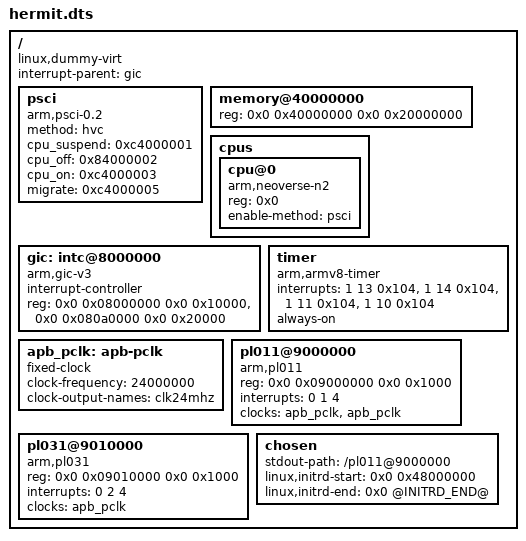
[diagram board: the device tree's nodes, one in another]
/*
 * N1.3: the board the Chitala image (Hermit) sees inside its VM: QEMU virt's
 * devices, as many as the VMM gives it and no more. RAM, one CPU, the GICv3
 * libvmm emulates, the architected timer (the guest uses the non-secure
 * physical one, passed through), the PL011 UART and the PL031 RTC (both
 * passed through), and PSCI. No PCI and no virtio: the guest finds none.
 * The image comes as the initrd; @INITRD_END@ is set when the image is built in.
 *
 * SPDX-License-Identifier: Apache-2.0
 */
/dts-v1/;

/ {
	interrupt-parent = <&gic>;
	#address-cells = <2>;
	#size-cells = <2>;
	compatible = "linux,dummy-virt";

	psci {
		compatible = "arm,psci-0.2", "arm,psci";
		method = "hvc";
		cpu_suspend = <0xc4000001>;
		cpu_off = <0x84000002>;
		cpu_on = <0xc4000003>;
		migrate = <0xc4000005>;
	};

	memory@40000000 {
		device_type = "memory";
		reg = <0x0 0x40000000 0x0 0x20000000>;
	};

	cpus {
		#address-cells = <1>;
		#size-cells = <0>;

		cpu@0 {
			device_type = "cpu";
			compatible = "arm,neoverse-n2";
			reg = <0x0>;
			enable-method = "psci";
		};
	};

	gic: intc@8000000 {
		compatible = "arm,gic-v3";
		#interrupt-cells = <3>;
		interrupt-controller;
		#address-cells = <2>;
		#size-cells = <2>;
		ranges;
		reg = <0x0 0x08000000 0x0 0x10000>,	/* distributor */
		      <0x0 0x080a0000 0x0 0x20000>;	/* redistributor: one vCPU */
	};

	timer {
		compatible = "arm,armv8-timer", "arm,armv7-timer";
		interrupts = <1 13 0x104>, <1 14 0x104>, <1 11 0x104>, <1 10 0x104>;
		always-on;
	};

	apb_pclk: apb-pclk {
		compatible = "fixed-clock";
		#clock-cells = <0>;
		clock-frequency = <24000000>;
		clock-output-names = "clk24mhz";
	};

	pl011@9000000 {
		compatible = "arm,pl011", "arm,primecell";
		reg = <0x0 0x09000000 0x0 0x1000>;
		interrupts = <0 1 4>;
		clock-names = "uartclk", "apb_pclk";
		clocks = <&apb_pclk>, <&apb_pclk>;
	};

	pl031@9010000 {
		compatible = "arm,pl031", "arm,primecell";
		reg = <0x0 0x09010000 0x0 0x1000>;
		interrupts = <0 2 4>;
		clock-names = "apb_pclk";
		clocks = <&apb_pclk>;
	};

	chosen {
		stdout-path = "/pl011@9000000";
		linux,initrd-start = <0x0 0x48000000>;
		linux,initrd-end = <0x0 @INITRD_END@>;
	};
};
